# Z20K14xM register map
Vendor: Zhixin Semiconductor; Series: Z20K14xM; File version: 0.1.0
CPU: CM4 r0p1, little endian, no MPU, FPU, 4 interrupt priority bits
Registers are 32-bit, read-write, reset 0x0 unless marked. A register's access mark holds for its fields unless they carry their own. Offsets are from the block's base; [hi:lo] are bit positions; {n}, {i} and the like mark numbered series.

## TIM0
Base 0x4000C000
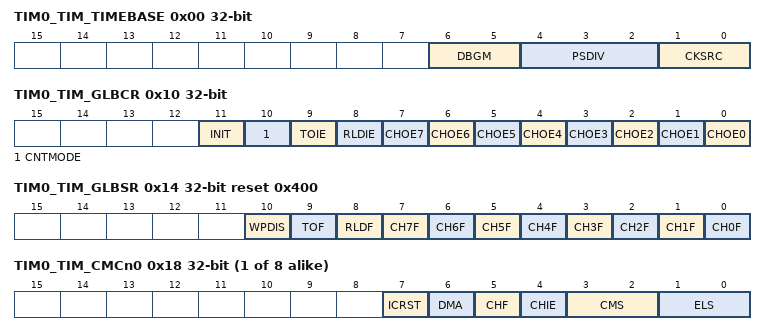
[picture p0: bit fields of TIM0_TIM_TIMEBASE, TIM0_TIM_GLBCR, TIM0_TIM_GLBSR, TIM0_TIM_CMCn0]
0x00 TIM0_TIM_TIMEBASE — TIM timebase register(TIM_TIMEBASE)
  [6:5] DBGM — Debug mode
  [4:2] PSDIV — Prescaler divider
  [1:0] CKSRC — clock source
0x04 TIM0_TIM_CNT — TIM counter register(TIM_CNT)
  [15:0] CNT — 16-bit counter
0x08 TIM0_TIM_CNTINIT — TIM counter initial value register(TIM_CNTINIT)
  [15:0] CNTINIT — 16-bit counter initial value
0x0C TIM0_TIM_MOD — TIM counter modulo value register(TIM_MOD)
  [15:0] MOD — 16-bit counter modulo value
0x10 TIM0_TIM_GLBCR — TIM global control register(TIM_GLBCR)
  [11] INIT — Initialize the channels output
  [10] CNTMODE — 16-bit counter counting mode
  [9] TOIE — Timer overflow interrupt enable
  [8] RLDIE — Reload interrupt enable
  [n] CHOE{n} (n=0..7) — Channel {n} output enable
0x14 TIM0_TIM_GLBSR reset 0x400 — TIM global status register(TIM_GLBSR)
  [10] WPDIS — Write protection disable
  [9] TOF — Timer overflow flag
  [8] RLDF — Reload flag
  [n] CH{n}F (n=0..7) — Channel {n} flag
{0x18+4i} TIM0_TIM_CMCn{i} (i=0..7) — TIM channel n mode configuration register(TIM_CMCn)
  [7] ICRST — Input capture reset
  [6] DMA — DMA enable
  [5] CHF — Channel flag
  [4] CHIE — Channel interrupt enable
  [3:2] CMS — Channel mode select
  [1:0] ELS — Edge or level select
{0x38+4i} TIM0_TIM_CCVn{i} (i=0..7) — TIM channel n capture/compare value register(TIM_CCVn)
  [15:0] CCV — Channel capture/compare value
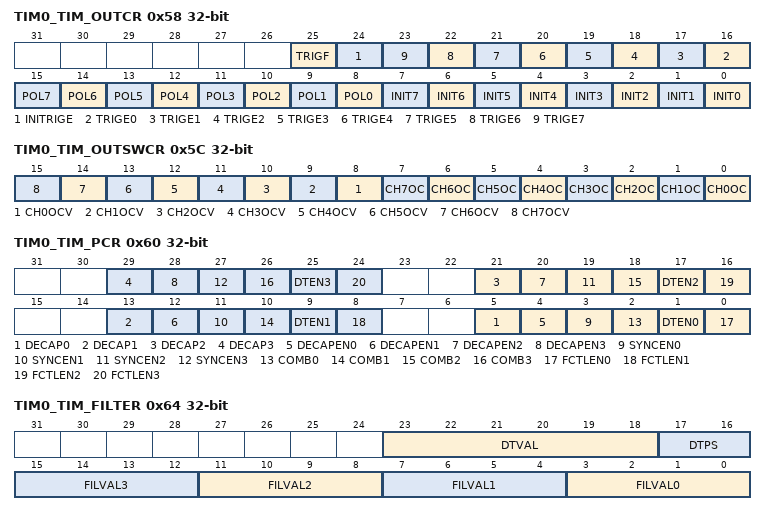
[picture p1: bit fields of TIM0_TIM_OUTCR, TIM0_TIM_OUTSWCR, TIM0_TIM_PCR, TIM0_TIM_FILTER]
0x58 TIM0_TIM_OUTCR — TIM output control register(TIM_OUTCR)
  [25] TRIGF — Channel output trigger flag
  [24] INITRIGE — Initialization trigger enable
  [n+16] TRIGE{n} (n=0..7) — Channel {n} match trigger enable
  [n+8] POL{n} (n=0..7) — Channel {n} output polarity
  [n] INIT{n} (n=0..7) — Channel {n} initialization value
0x5C TIM0_TIM_OUTSWCR — TIM channel output software control register(TIM_OUTSWCR)
  [n+8] CH{n}OCV (n=0..7) — Channel {n} output software control value
  [n] CH{n}OC (n=0..7) — Channel {n} output software control enable
0x60 TIM0_TIM_PCR — TIM pairs of channel control register(TIM_PCR)
  [8n+5] DECAP{n} (n=0..3) — Dual edge capture mode for pairs of channel {n}
  [8n+4] DECAPEN{n} (n=0..3) — Dual edge capture enable for pairs of channel {n}
  [8n+3] SYNCEN{n} (n=0..3) — Synchronization enable for pairs of channel {n}
  [8n+2] COMB{n} (n=0..3) — Combine enable for pairs of channel {n}
  [8n+1] DTEN{n} (n=0..3) — Deadtime insertion enable for pairs of channel {n}
  [8n] FCTLEN{n} (n=0..3) — Fault control enabled for pairs of channel {n}
0x64 TIM0_TIM_FILTER — TIM input filter register(TIM_FILTER)
  [23:18] DTVAL — Deadtime insertion value
  [17:16] DTPS — Deadtime prescaler value
  [4n+3:4n] FILVAL{n} (n=0..3) — Channel {n} input filter value
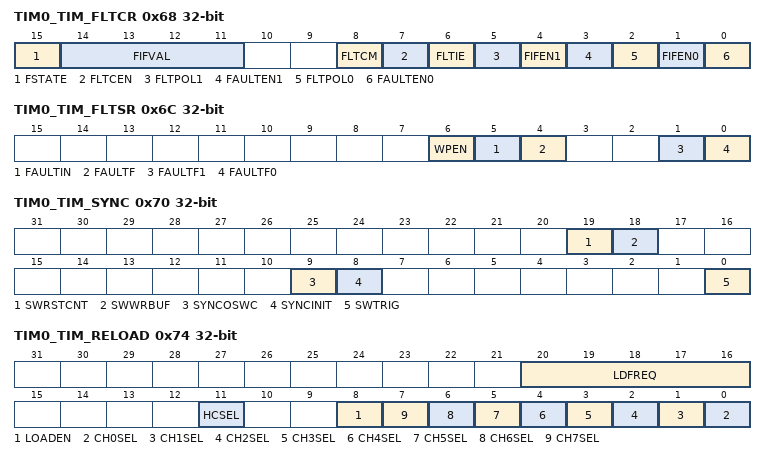
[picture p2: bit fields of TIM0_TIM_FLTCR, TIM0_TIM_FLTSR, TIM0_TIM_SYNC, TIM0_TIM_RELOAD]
0x68 TIM0_TIM_FLTCR — TIM fault control register(TIM_FLTCR)
  [15] FSTATE — Fault output status
  [14:11] FIFVAL — Fault input filter value
  [8] FLTCM — Falut clear mode
  [7] FLTCEN — Falut control enable
  [6] FLTIE — Fault interrupt enable
  [5] FLTPOL1 — Fault input channel 1 polarity
  [4] FIFEN1 — Fault input filter enable 1
  [3] FAULTEN1 — Fault input enable 1
  [2] FLTPOL0 — Fault input channel 0 polarity
  [1] FIFEN0 — Fault input filter enable 0
  [0] FAULTEN0 — Fault input enable 0
0x6C TIM0_TIM_FLTSR — TIM fault status register(TIM_FLTSR)
  [6] WPEN — Write protection enable
  [5] FAULTIN — Fault inputs value
  [4] FAULTF — Fault detection flag
  [1] FAULTF1 — Fault detection flag of fault channel 1
  [0] FAULTF0 — Fault detection flag of fault channel 0
0x70 TIM0_TIM_SYNC — TIM synchronization register(TIM_SYNC)
  [19] SWRSTCNT — Software trigger activate CNT register synchronization
  [18] SWWRBUF — Software trigger activate write buffer synchronization
  [9] SYNCOSWC — OUTSWCR register synchronization
  [8] SYNCINIT — CNTINIT register synchronization
  [0] SWTRIG — PWM synchronization software trigger
0x74 TIM0_TIM_RELOAD — TIM reload register(TIM_RELOAD)
  [20:16] LDFREQ — Reload frequency
  [11] HCSEL — Half cycle reload select
  [8] LOADEN — Reload enable
  [n] CH{n}SEL (n=0..7) — Channel {n} select
0x78 TIM0_TIM_HCV — TIM half cycle reload value register(TIM_HCV)
  [15:0] HCV — Half cycle reload value

## TIM1
Base 0x4000D000
Registers as TIM0 (with TIM0 read as TIM1).

## TIM2
Base 0x40018000
Registers as TIM0 (with TIM0 read as TIM2).

## TIM3
Base 0x40019000
Registers as TIM0 (with TIM0 read as TIM3).
